# SC32F10T_10G register map
File version: 1.0
CPU: CM0+ r0p1, little endian, MPU, no FPU, 4 interrupt priority bits
Registers are 32-bit, access not given, reset 0x0 unless marked. A register's access mark holds for its fields unless they carry their own. Offsets are from the block's base; [hi:lo] are bit positions; {n}, {i} and the like mark numbered series.

## TIM7
Base 0x400211C0
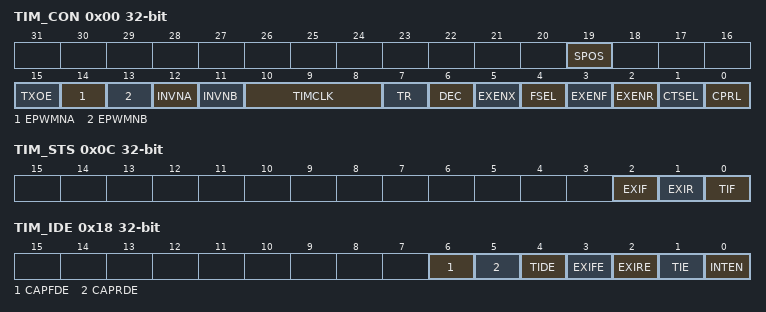
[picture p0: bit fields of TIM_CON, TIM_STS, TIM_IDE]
0x00 TIM_CON rw — 定时器控制寄存器
  [19] SPOS — TIM2管脚映射控制位@ TIM2_CON 信号SPOS值T2CAP/T2SPOS=0PA10SPOS=1PA12TIM3管脚映射控制位@ TIM3_CON 信号SPOS值T3CAP/T3SPOS=0PA0SPOS=1PA13TIM7管脚映射控制位@ TIM7
  [15] TXOE — Tn引脚信号方向控制位0：Tn作为时钟输入口或I/O 端口1：Tn用于可编程时钟输出
  [14] EPWMNA — Tn_PWMA所在管脚 PWM波形输出使能位0：关闭1：使能
  [13] EPWMNB — TnEX_PWMB所在管脚 PWM波形输出使能位0：关闭1：使能
  [12] INVNA — TPWMnA波形输出反向控制位0：正常1：波形输出反向
  [11] INVNB — TPWMnB波形输出反向控制位0：正常1：波形输出反向
  [10:8] TIMCLK — TIM时钟频率档位控制位000：fTIM/1001：fTIM/2010：fTIM/4011：fTIM/8100：fTIM/16101：fTIM/32110：fTIM/64111：fTIM/128fTIM对应的时钟可能为fPCLK 或Tn输入
  [7] TR — TIMn开始/停止控制位，n=0~7 0：停止TIMn / TPWMn计数器 1：开始TIMn / TPWMn计数器
  [6] DEC — 递增/递减方向控制位 0：TIMn为递增的定时/计数器 1：TIMn作为递增/递减的定时/计数器，TnEX用来选择计数方向
  [5] EXENX — TnEX设置位，n=0该位在不同模式下作用不同：重载模式：（CPRL = 0） 该位用于控制TnEX引脚上的外部事件输入(下降沿)，用作重载允许/禁止控制： 0：忽略TnEX引脚上的事件 1：检测到TnEX引脚上一个下降沿，产生一个重载捕获模式：（CPRL = 1） 该位用作TnEX下降沿信号捕获选通位： 0：忽略TnEX引脚上的事件 1：当FSEL = 1，检测到TnEX引脚上一个下降沿，产生一
  [4] FSEL — 下降沿信号选择位该位仅在捕获模式（CPRL=1)下有效 0：检测到Tn引脚上一个下降沿，产生一个捕获。忽略TnEX引脚上的事件 1：检测到TnEX引脚上一个下降沿，产生一个捕获。忽略Tn引脚上的事件
  [3] EXENF — 下降沿信号捕获使能位:0：忽略Tn引脚上的事件 1：检测到Tn引脚上一个下降沿，产生一个捕获，EXIF被置起，TnCNT寄存器的值捕获到寄存器FCAP里
  [2] EXENR — Tn引脚上的上升沿信号捕获使能位 0：忽略Tn引脚上的事件 1：检测到Tn引脚上一个上升沿，产生一个捕获，EXIR被置起，TnCNT寄存器的值捕获到寄存器RCAP里
  [1] CTSEL — 定时器/计数器选定位 0：定时器方式 1：计数器方式
  [0] CPRL — 捕获/重载方式设置位 0：重载功能 1：捕获功能
0x04 TIM_CNT — 定时器计数值寄存器
0x08 TIM_RLD — 定时器重载寄存器
0x0C TIM_STS rw — 定时标志位寄存器
  [2] EXIF — 外部事件输入下降沿被检测到的标志位该位由硬件置1，通过软件写1清0。 0：无外部事件输入 1：检测到外部输入(如果EXENF = 1，由硬件设1) 注意：捕获模式下，该位软件清0之前不允许更新TnFCAP值
  [1] EXIR — Tn引脚外部事件输入上升沿被检测到的标志位该位由硬件置1，通过软件写1清0。 0：无外部事件输入 1：检测到外部输入(如果EXENR = 1，由硬件设1) 注意：捕获模式下，该位软件清0之前不允许更新TnRCAP值
  [0] TIF — 定时器溢出标志位该位由硬件置1，通过软件写1清0。 0：无溢出(必须由软件清0) 1：溢出(如果RCLK = 0和TCLK = 0，由硬件设1)
0x10 TIM_PDTA_RCAP — TIMER Rise Caputre Key register
0x14 TIM_PDTB_FCAP — TIMER fall Caputre register
0x18 TIM_IDE rw — TIMn的中断使能及DMA控制寄存器
  [6] CAPFDE — 下降沿捕获事件触发DMA请求使能位 0：下降沿捕获事件禁止产生DMA请求 1：产生新的下降沿捕获时，触发DMA请求，DMA搬运FCAP寄存器的值
  [5] CAPRDE — 上升沿捕获事件触发DMA请求使能位 0：上升沿捕获事件禁止产生DMA请求 1：产生新的下降沿捕获时，触发DMA请求，DMA搬运RCAP寄存器的值
  [4] TIDE — 定时器溢出事件触发DMA请求使能位 0：定时器溢出禁止产生DMA请求 1：定时器溢出允许产生DMA请求
  [3] EXIFE — 外部事件输入下降沿中断开关 0：禁止下降沿中断 1：使能下降沿中断
  [2] EXIRE — 外部事件输入上升沿中断开关 0：禁止上升沿中断 1：使能上升沿中断
  [1] TIE — 定时器溢出中断开关 0：禁止溢出中断 1：使能溢出中断
  [0] INTEN — 中断请求 CPU的使能控制位0：禁止中断请求1：使能中断请求

## PWM0
Base 0x40020200
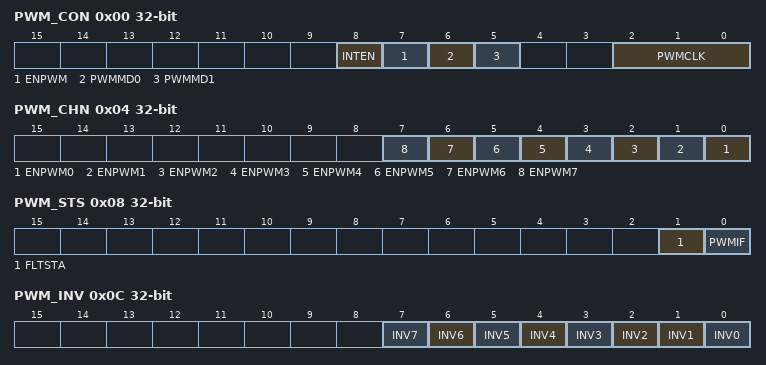
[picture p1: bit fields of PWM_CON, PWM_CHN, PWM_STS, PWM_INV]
0x00 PWM_CON rw — PWM0控制寄存器
  [8] INTEN — 中断请求 CPU 的使能控制位0：禁止中断请求1：使能中断请求
  [7] ENPWM — PWM模块开关控制位1：允许Clock进到 PWM 单元，PWM处于工作状态，PWM输出口的状态由寄存器ENPWMx控制（x=0~7）0：PWM单元停止工作，PWM计数器清0，全部 PWM输出口设置为GPIO状态
  [6] PWMMD0 — PWM波形对齐模式选择位0：边沿对齐模式1：中心对齐模式
  [5] PWMMD1 — PWM波形互补模式设置位0：独立模式1：互补模式
  [2:0] PWMCLK
0x04 PWM_CHN rw — PWM0通道设置寄存器
  [n] ENPWM{n} (n=0..7)
0x08 PWM_STS rw — PWM0状态标志寄存器
  [1] FLTSTA — PWM故障检测状态标志位0：PWM处于正常输出状态；1：故障检测有效，PWM输出处于高阻状态，如果处于锁存模式，此位可软件清0
  [0] PWMIF — PWM中断请求标志位该位由硬件置1，通过软件写1清0。当PWM 计数器溢出时(即：计数值超过 PWMPD)，该位由硬件置1。如果此时PWM0_CON.INTEN = 1，将产生 PWM0 中断 。
0x0C PWM_INV rw — PWM0波形输出反向控制寄存器
  [n] INV{n} (n=2..7)
  [1] INV1 — PWM0x波形输出反向控制1：PWM0x波形输出反向0：PWM0x波形输出不反向
  [0] INV0
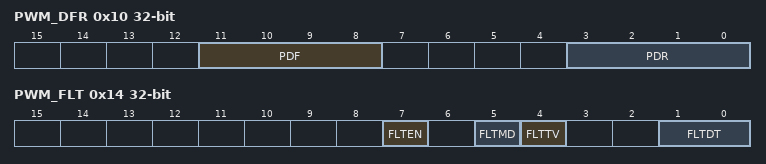
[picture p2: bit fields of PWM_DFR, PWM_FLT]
0x10 PWM_DFR rw — PWM0死区设置寄存器
  [11:8] PDF — 下降沿死区时间设置位此位仅在互补模式设置有效：PWM下降沿死区时间= 4*PDF[3:0] / fPCLK
  [3:0] PDR — 上升沿死区时间设置位此位仅在互补模式设置有效：PWM 上升沿死区时间= 4*PDR[3:0] / fPCLK
0x14 PWM_FLT rw — PWM0故障检测设置寄存器
  [7] FLTEN — PWM故障检测功能控制位0：故障检测功能关闭1：故障检测功能开启
  [5] FLTMD — PWM故障检测模式设置位0：锁存模式，当故障输入有效时，故障检测状态标志位FLTSTA由硬件置1，PWM停止输出，当故障输入无效时FLTSTA状态不变1：立即模式：当故障输入有效时，故障检测状态标志位FLTSTA由硬件置1，PWM停止输出，当故障输入无效时FLTSTA状态立刻被硬件清0，PWM波形将在PWM计数器计数到0时恢复输出
  [4] FLTTV — PWM故障检测电平选择位0：故障检测低电平有效1：故障检测高电平有效
  [1:0] FLTDT — PWM故障检测输入信号滤波时间设置00：滤波时间为001：滤波时间为1us10：滤波时间为4us11：滤波时间为16us
0x18 PWM_CYCLE — PWM0周期寄存器
0x30 PWM_DT — PWM Duty register

## PWM1 — PWM0
Base 0x40022300
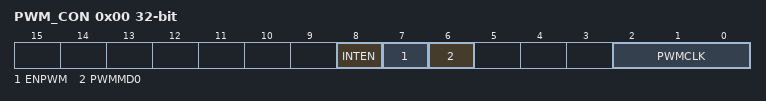
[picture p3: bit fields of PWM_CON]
0x00 PWM_CON rw — PWM0控制寄存器
  [8] INTEN — 中断请求 CPU 的使能控制位0：禁止中断请求1：使能中断请求
  [7] ENPWM — PWM模块开关控制位1：允许Clock进到 PWM 单元，PWM处于工作状态，PWM输出口的状态由寄存器ENPWMx控制（x=0~7）0：PWM单元停止工作，PWM计数器清0，全部 PWM输出口设置为GPIO状态
  [6] PWMMD0 — PWM波形对齐模式选择位0：边沿对齐模式1：中心对齐模式
  [2:0] PWMCLK
0x04 PWM_CHN — PWM0通道设置寄存器
0x08 PWM_STS rw — PWM0状态标志寄存器
  [0] PWMIF — PWM中断请求标志位该位由硬件置1，通过软件写1清0。当PWM 计数器溢出时(即：计数值超过 PWMPD)，该位由硬件置1。如果此时PWM0_CON.INTEN = 1，将产生 PWM0 中断 。
0x0C PWM_INV — PWM0波形输出反向控制寄存器
0x10 PWM_DFR — PWM0死区设置寄存器
0x14 PWM_FLT — PWM0故障检测设置寄存器
0x18 PWM_CYCLE — PWM0周期寄存器
0x30 PWM_DT — PWM Duty register
